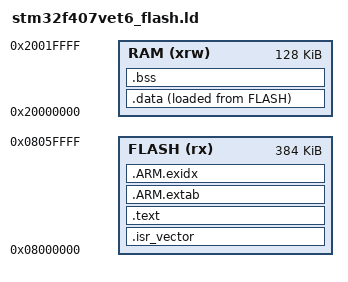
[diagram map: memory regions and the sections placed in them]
ENTRY(Reset_Handler)

MEMORY
{
    /* Sector 7 (0x08060000..0x0807FFFF) stores bypass calibration. */
    FLASH (rx)  : ORIGIN = 0x08000000, LENGTH = 384K
    RAM   (xrw) : ORIGIN = 0x20000000, LENGTH = 128K
}

_estack = ORIGIN(RAM) + LENGTH(RAM);

SECTIONS
{
    .isr_vector :
    {
        . = ALIGN(4);
        KEEP(*(.isr_vector))
        . = ALIGN(4);
    } > FLASH

    .text :
    {
        . = ALIGN(4);
        *(.text .text.*)
        *(.rodata .rodata.*)
        KEEP(*(.init))
        KEEP(*(.fini))
        KEEP(*(.preinit_array .preinit_array.*))
        KEEP(*(.init_array .init_array.*))
        KEEP(*(.fini_array .fini_array.*))
        . = ALIGN(4);
        _etext = .;
    } > FLASH

    .ARM.extab :
    {
        *(.ARM.extab* .gnu.linkonce.armextab.*)
    } > FLASH

    .ARM.exidx :
    {
        __exidx_start = .;
        *(.ARM.exidx*)
        __exidx_end = .;
    } > FLASH

    .data :
    {
        . = ALIGN(4);
        _sdata = .;
        *(.data .data.*)
        . = ALIGN(4);
        _edata = .;
    } > RAM AT> FLASH
    _sidata = LOADADDR(.data);

    .bss (NOLOAD) :
    {
        . = ALIGN(4);
        _sbss = .;
        *(.bss .bss.*)
        *(COMMON)
        . = ALIGN(4);
        _ebss = .;
    } > RAM

    . = ALIGN(8);
    _end = .;
    end = .;

    /DISCARD/ :
    {
        *(.comment)
        *(.note*)
    }
}

ASSERT(_estack - _end >= 0x1000, "RAM overflow or less than 4 KiB stack remains")
ASSERT(LOADADDR(.data) + SIZEOF(.data) <= ORIGIN(FLASH) + LENGTH(FLASH),
       "FLASH overflow")
